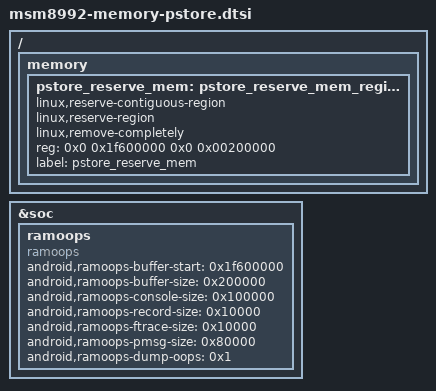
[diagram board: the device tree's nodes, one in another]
/ {
	memory {
		pstore_reserve_mem: pstore_reserve_mem_region@1f600000 {
			linux,reserve-contiguous-region;
			linux,reserve-region;
			linux,remove-completely;
			reg = <0x0 0x1f600000 0x0 0x00200000>;
			label = "pstore_reserve_mem";
		};
	};
};

&soc {
	ramoops {
		compatible = "ramoops";
		status = "ok";

		android,ramoops-buffer-start = <0x1f600000>;
		android,ramoops-buffer-size = <0x200000>;
		android,ramoops-console-size = <0x100000>;
		android,ramoops-record-size = <0x10000>;
		android,ramoops-ftrace-size = <0x10000>;
		android,ramoops-pmsg-size = <0x80000>;
		android,ramoops-dump-oops = <0x1>;
	};
};
